# R7FA4L1BD register map
Vendor: Renesas Electronics Corporation; Series: RA4; File version: 0.90.02
CPU: CM33 r0p4, little endian, MPU, FPU, VTOR, 4 interrupt priority bits, 96 interrupts
Registers are 32-bit, read-write, reset 0x0 unless marked. A register's access mark holds for its fields unless they carry their own. Offsets are from the block's base; [hi:lo] are bit positions; {n}, {i} and the like mark numbered series; 'fields as' and 'values as' point back to an identical list.

## POEG — Port Output Enable Module for GPT
Base 0x4008A000
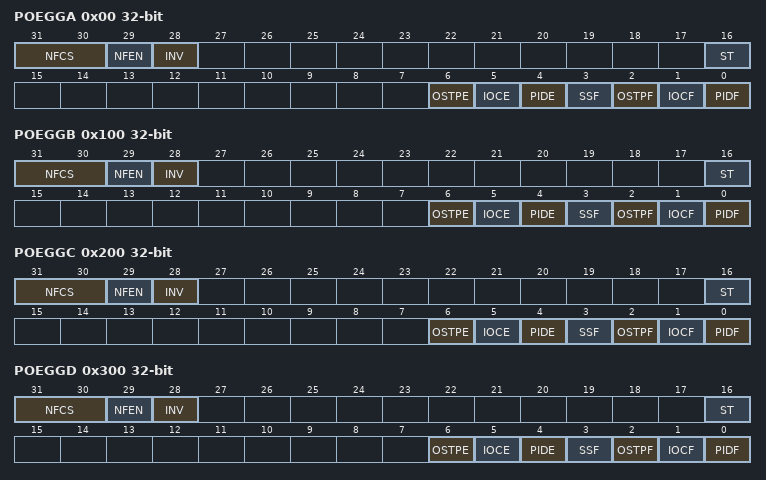
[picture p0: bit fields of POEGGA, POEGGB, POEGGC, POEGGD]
0x00 POEGGA — POEG Group A Setting Register
  [31:30] NFCS — Noise Filter Clock Select
  [29] NFEN — Noise Filter Enable
  [28] INV — GTETRGn Input Reverse
  [16] ST ro — GTETRGn Input Status Flag
  [6] OSTPE — Oscillation Stop Detection Enable
  [5] IOCE — Enable for GPT Output,Disable Request
  [4] PIDE — Port Input Detection Enable
  [3] SSF — Software Stop Flag
  [2] OSTPF — Oscillation Stop Detection Flag
  [1] IOCF — Detection Flag for GPT Output,Disable Request
  [0] PIDF — Port Input Detection Flag
0x100 POEGGB — POEG Group B Setting Register
  fields as POEGGA
0x200 POEGGC — POEG Group C Setting Register
  fields as POEGGA
0x300 POEGGD — POEG Group D Setting Register
  fields as POEGGA

## UARTA
Base 0x40097000
{0x0+8i} TXBA{i} (i=0..1) 8-bit reset 0xFF — Transmit Buffer Register {i}
{0x1+8i} RXBA{i} (i=0..1) 8-bit ro reset 0xFF — Receive Buffer Register {i}
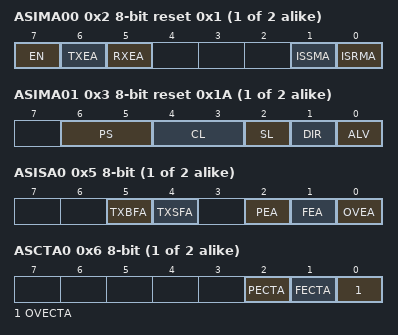
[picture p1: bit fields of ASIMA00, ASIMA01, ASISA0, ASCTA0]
{0x2+8i} ASIMA{i}0 (i=0..1) 8-bit reset 0x1 — Operation Mode Setting Register n0
  [7] EN — UART operation enable
  [6] TXEA — Transmission enable
  [5] RXEA — Reception enable
  [1] ISSMA — Transmit interrupt mode select
  [0] ISRMA — Receive interrupt mode select
{0x3+8i} ASIMA{i}1 (i=0..1) 8-bit reset 0x1A — Operation Mode Setting Register n1
  [6:5] PS — Transmission and reception parity bit setting
  [4:3] CL — Transmission and reception character length setting
  [2] SL — Transmission stop bit length setting
  [1] DIR — Transmission and reception order setting
  [0] ALV — Transmission and reception level setting
{0x4+8i} BRGCA{i} (i=0..1) 8-bit reset 0xFF — Baud Rate Generator Control Register {i}
{0x5+8i} ASISA{i} (i=0..1) 8-bit ro — Status Register {i}
  [5] TXBFA — Transmit buffer data flag
  [4] TXSFA — Transmit shift register data flag
  [2] PEA — Parity error flag
  [1] FEA — Framing error flag
  [0] OVEA — Overrun error flag
{0x6+8i} ASCTA{i} (i=0..1) 8-bit — Status Clear Trigger Register {i}
  [2] PECTA — Parity error flag clear trigger
  [1] FECTA — Framing error flag clear trigger
  [0] OVECTA — Overrun error flag clear trigger
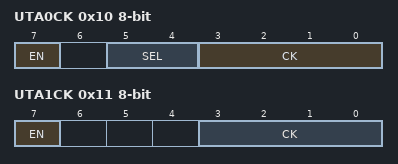
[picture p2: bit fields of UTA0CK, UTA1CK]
0x10 UTA0CK 8-bit — UARTA Clock Select Register 0
  [7] EN
  [5:4] SEL — fSEL clock select
  [3:0] CK — UARTA0 operation clock select (fUTA0)
0x11 UTA1CK 8-bit — UARTA Clock Select Register 1
  [7] EN — UARTA1 clock output function enable
  [3:0] CK — UARTA1 operation clock select (fUTA1)

## SSIE0 — Serial Sound Interface Enhanced (SSIE)
Base 0x4009D000
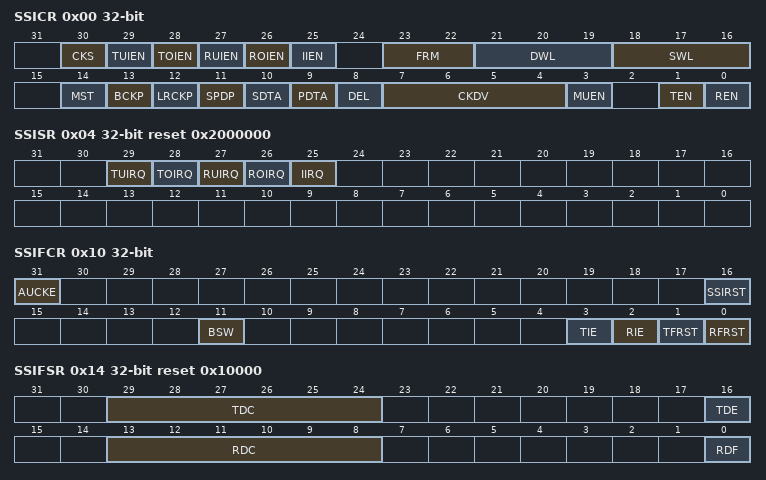
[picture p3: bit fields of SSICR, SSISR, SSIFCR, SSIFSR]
0x00 SSICR — Control Register
  [30] CKS — Selects an Audio Clock for Master,mode Communication
  [29] TUIEN — Transmit Underflow Interrupt Output Enable
  [28] TOIEN — Transmit Overflow Interrupt Output Enable
  [27] RUIEN — Receive Underflow Interrupt Output Enable
  [26] ROIEN — Receive Overflow Interrupt Output Enable
  [25] IIEN — Idle Mode Interrupt Output Enable
  [23:22] FRM — Selects Frame Word Number
  [21:19] DWL — Selects Data Word Length
  [18:16] SWL — Selects System Word Length
  [14] MST — Master Enable
  [13] BCKP — Selects Bit Clock Polarity
  [12] LRCKP — Selects the Initial Value and Polarity of LR Clock/Frame Synchronization Signal
  [11] SPDP — Selects Serial Padding Polarity
  [10] SDTA — Selects Serial Data Alignment
  [9] PDTA — Selects Placement Data Alignment
  [8] DEL — Selects Serial Data Delay
  [7:4] CKDV — Selects Bit Clock Division Ratio
  [3] MUEN — Mute Enable
  [1] TEN — Transmission Enable
  [0] REN — Reception Enable
0x04 SSISR reset 0x2000000 — Status Register
  [29] TUIRQ — Transmit Underflow Error Status flag
  [28] TOIRQ — Transmit Overflow Error Status Flag
  [27] RUIRQ — Receive Underflow Error Status Flag
  [26] ROIRQ — Receive Overflow Error Status Flag
  [25] IIRQ ro — Idle Mode Status Flag
0x10 SSIFCR — FIFO Control Register
  [31] AUCKE — AUDIO_MCK Enable in Master,mode Communication
  [16] SSIRST — Software Reset
  [11] BSW — Byte Swap Enable
  [3] TIE — Transmit Data Empty Interrupt Output Enable
  [2] RIE — Receive Data Full Interrupt Output Enable
  [1] TFRST — Transmit FIFO Data Register Reset
  [0] RFRST — Receive FIFO Data Register Reset
0x14 SSIFSR reset 0x10000 — FIFO Status Register
  [29:24] TDC ro — Transmit Data Count
  [16] TDE — Transmit Data Empty Flag
  [13:8] RDC ro — Receive Data Count
  [0] RDF — Receive Data Full Flag
0x18 SSIFTDR wo — Transmit FIFO Data Register
  [31:0] SSIFTDR — Transmit FIFO Data
0x1C SSIFRDR ro — Receive FIFO Data Register
  [31:0] SSIFRDR — Receive FIFO Data
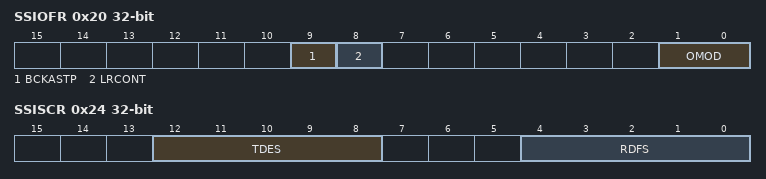
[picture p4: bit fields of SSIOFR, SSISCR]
0x20 SSIOFR — Audio Format Register
  [9] BCKASTP — Whether to Enable Stopping BCK Output When SSIE is in Idle Status
  [8] LRCONT — Whether to Enable LRCK/FS Continuation
  [1:0] OMOD — Audio Format Select
0x24 SSISCR — Status Control Register
  [12:8] TDES — TDE Setting Condition Select
  [4:0] RDFS — RDF Setting Condition Select
